AUTOSAR XML (schema 4-0-3)
standard types defined: Boolean, uint8, UInt16, UInt32, UInt8
package /AUTOSAR_Platform/DataConstrs
  range DC_Boolean: raw 0..1
  range DC_UInt16: raw 0..65535
  range DC_UInt8: raw 0..255
package /PATAC/Facility/DataTypes/Implementation
  compu method COMPU_Boolean: 0=FALSE, 1=TRUE
  unit NoUnit: factor-si-to-unit=1, offset-si-to-unit=0
package /PATAC/MSM/ComponentTypes
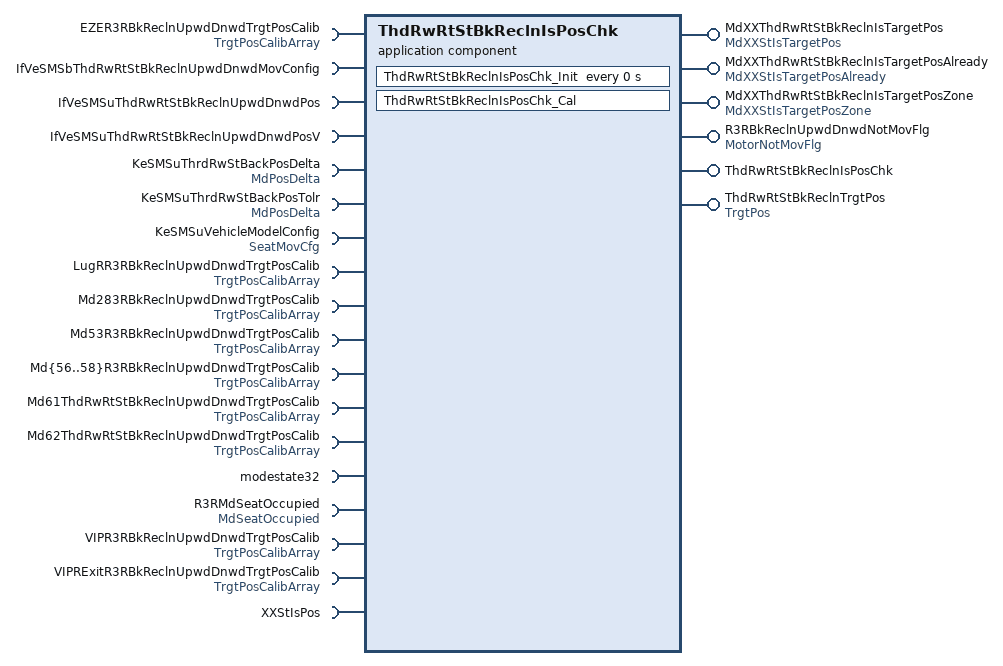
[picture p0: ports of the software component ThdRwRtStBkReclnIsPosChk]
  application sw component type ThdRwRtStBkReclnIsPosChk
    6 x provide port:
      MdXXThdRwRtStBkReclnIsTargetPos: nonqueued-sender-com-spec=data-element=MdXXStIsTargetPos/Val, provided-interface=MdXXStIsTargetPos
      MdXXThdRwRtStBkReclnIsTargetPosAlready: nonqueued-sender-com-spec=data-element=MdXXStIsTargetPosAlready/Val, provided-interface=MdXXStIsTargetPosAlready
      MdXXThdRwRtStBkReclnIsTargetPosZone: nonqueued-sender-com-spec=data-element=MdXXStIsTargetPosZone/Val, provided-interface=MdXXStIsTargetPosZone
      R3RBkReclnUpwdDnwdNotMovFlg: nonqueued-sender-com-spec{data-element=MotorNotMovFlg/Val, init-value=0}, provided-interface=MotorNotMovFlg
      ThdRwRtStBkReclnIsPosChk: server-com-spec{operation=Cal, queue-length=1}, provided-interface=ThdRwRtStBkReclnIsPosChk
      ThdRwRtStBkReclnTrgtPos: nonqueued-sender-com-spec{data-element=TrgtPos/Val, init-value=4095}, provided-interface=TrgtPos
    20 x require port:
      EZER3RBkReclnUpwdDnwdTrgtPosCalib: nonqueued-receiver-com-spec{data-element=TrgtPosArray, filter=data-filter-type=ALWAYS, init-value=[4095, 4095, 4095]}, required-interface=TrgtPosCalibArray
      IfVeSMSbThdRwRtStBkReclnUpwdDnwdMovConfig: nonqueued-receiver-com-spec{data-element=IfVeSMSbThdRwRtStBkReclnUpwdDnwdMovConfig/Val, filter=data-filter-type=ALWAYS, init-value=0}, required-interface=IfVeSMSbThdRwRtStBkReclnUpwdDnwdMovConfig
      IfVeSMSuThdRwRtStBkReclnUpwdDnwdPos: nonqueued-receiver-com-spec{data-element=IfVeSMSuThdRwRtStBkReclnUpwdDnwdPos/Val, filter=data-filter-type=ALWAYS, init-value=0}, required-interface=IfVeSMSuThdRwRtStBkReclnUpwdDnwdPos
      IfVeSMSuThdRwRtStBkReclnUpwdDnwdPosV: nonqueued-receiver-com-spec{data-element=IfVeSMSuThdRwRtStBkReclnUpwdDnwdPosV/Val, filter=data-filter-type=ALWAYS, init-value=0}, required-interface=IfVeSMSuThdRwRtStBkReclnUpwdDnwdPosV
      KeSMSuThrdRwStBackPosDelta: parameter-require-com-spec{init-value=150, parameter=MdPosDelta/Val}, required-interface=MdPosDelta
      KeSMSuThrdRwStBackPosTolr: parameter-require-com-spec{init-value=150, parameter=MdPosDelta/Val}, required-interface=MdPosDelta
      KeSMSuVehicleModelConfig: parameter-require-com-spec{init-value=2, parameter=SeatMovCfg/Val}, required-interface=SeatMovCfg
      LugRR3RBkReclnUpwdDnwdTrgtPosCalib: nonqueued-receiver-com-spec{data-element=TrgtPosArray, filter=data-filter-type=ALWAYS, init-value=[4095, 4095, 4095]}, required-interface=TrgtPosCalibArray
      Md283RBkReclnUpwdDnwdTrgtPosCalib: nonqueued-receiver-com-spec{data-element=TrgtPosArray, filter=data-filter-type=ALWAYS, init-value=[4095, 4095, 4095]}, required-interface=TrgtPosCalibArray
      Md53R3RBkReclnUpwdDnwdTrgtPosCalib: nonqueued-receiver-com-spec{data-element=TrgtPosArray, filter=data-filter-type=ALWAYS, init-value=[4095, 4095, 4095]}, required-interface=TrgtPosCalibArray
      Md{56..58}R3RBkReclnUpwdDnwdTrgtPosCalib: nonqueued-receiver-com-spec{data-element=TrgtPosArray, filter=data-filter-type=ALWAYS, init-value=[4095, 4095, 4095]}, required-interface=TrgtPosCalibArray
      Md61ThdRwRtStBkReclnUpwdDnwdTrgtPosCalib: nonqueued-receiver-com-spec{data-element=TrgtPosArray, filter=data-filter-type=ALWAYS, init-value=[4095, 4095, 4095]}, required-interface=TrgtPosCalibArray
      Md62ThdRwRtStBkReclnUpwdDnwdTrgtPosCalib: nonqueued-receiver-com-spec{data-element=TrgtPosArray, filter=data-filter-type=ALWAYS, init-value=[4095, 4095, 4095]}, required-interface=TrgtPosCalibArray
      modestate32: nonqueued-receiver-com-spec{data-element=modestate32/Val, filter=data-filter-type=ALWAYS, init-value=0}, required-interface=modestate32
      R3RMdSeatOccupied: nonqueued-receiver-com-spec{data-element=MdSeatOccupied/Val, filter=data-filter-type=ALWAYS, init-value=0}, required-interface=MdSeatOccupied
      VIPR3RBkReclnUpwdDnwdTrgtPosCalib: nonqueued-receiver-com-spec{data-element=TrgtPosArray, filter=data-filter-type=ALWAYS, init-value=[4095, 4095, 4095]}, required-interface=TrgtPosCalibArray
      VIPRExitR3RBkReclnUpwdDnwdTrgtPosCalib: nonqueued-receiver-com-spec{data-element=TrgtPosArray, filter=data-filter-type=ALWAYS, init-value=[4095, 4095, 4095]}, required-interface=TrgtPosCalibArray
      XXStIsPos: client-com-spec=Get, required-interface=XXStIsPos
    behavior ThdRwRtStBkReclnIsPosChk_InternalBehavior
      operation invoked event OIT_ThdRwRtStBkReclnIsPosChk_Cal_ThdRwRtStBkReclnIsPosChk_Cal: start-on-event=ThdRwRtStBkReclnIsPosChk_Cal, operation=ThdRwRtStBkReclnIsPosChk.Cal
      timing event ThdRwRtStBkReclnIsPosChk_InitEvent: start-on-event=ThdRwRtStBkReclnIsPosChk_Init, period=0
      runnable ThdRwRtStBkReclnIsPosChk_Cal
        data-receive-point-by-arguments:
          16 x access:
            REC_EZER3RBkReclnUpwdDnwdTrgtPosCalib_TrgtPosArray: accessed-variable=EZER3RBkReclnUpwdDnwdTrgtPosCalib.TrgtPosArray
            REC_IfVeSMSbThdRwRtStBkReclnUpwdDnwdMovConfig_Val: accessed-variable=IfVeSMSbThdRwRtStBkReclnUpwdDnwdMovConfig.Val
            REC_IfVeSMSuThdRwRtStBkReclnUpwdDnwdPos_Val: accessed-variable=IfVeSMSuThdRwRtStBkReclnUpwdDnwdPos.Val
            REC_IfVeSMSuThdRwRtStBkReclnUpwdDnwdPosV_Val: accessed-variable=IfVeSMSuThdRwRtStBkReclnUpwdDnwdPosV.Val
            REC_LugRR3RBkReclnUpwdDnwdTrgtPosCalib_TrgtPosArray: accessed-variable=LugRR3RBkReclnUpwdDnwdTrgtPosCalib.TrgtPosArray
            REC_Md283RBkReclnUpwdDnwdTrgtPosCalib_TrgtPosArray: accessed-variable=Md283RBkReclnUpwdDnwdTrgtPosCalib.TrgtPosArray
            REC_Md53R3RBkReclnUpwdDnwdTrgtPosCalib_TrgtPosArray: accessed-variable=Md53R3RBkReclnUpwdDnwdTrgtPosCalib.TrgtPosArray
            REC_Md{56..58}R3RBkReclnUpwdDnwdTrgtPosCalib_TrgtPosArray: accessed-variable=Md{56..58}R3RBkReclnUpwdDnwdTrgtPosCalib.TrgtPosArray
            REC_Md61ThdRwRtStBkReclnUpwdDnwdTrgtPosCalib_TrgtPosArray: accessed-variable=Md61ThdRwRtStBkReclnUpwdDnwdTrgtPosCalib.TrgtPosArray
            REC_Md62ThdRwRtStBkReclnUpwdDnwdTrgtPosCalib_TrgtPosArray: accessed-variable=Md62ThdRwRtStBkReclnUpwdDnwdTrgtPosCalib.TrgtPosArray
            REC_modestate32_Val: accessed-variable=modestate32.Val
            REC_R3RMdSeatOccupied_Val: accessed-variable=R3RMdSeatOccupied.Val
            REC_VIPR3RBkReclnUpwdDnwdTrgtPosCalib_TrgtPosArray: accessed-variable=VIPR3RBkReclnUpwdDnwdTrgtPosCalib.TrgtPosArray
            REC_VIPRExitR3RBkReclnUpwdDnwdTrgtPosCalib_TrgtPosArray: accessed-variable=VIPRExitR3RBkReclnUpwdDnwdTrgtPosCalib.TrgtPosArray
        data-send-points:
          5 x access:
            SEND_MdXXThdRwRtStBkReclnIsTargetPos_Val: accessed-variable=MdXXThdRwRtStBkReclnIsTargetPos.Val
            SEND_MdXXThdRwRtStBkReclnIsTargetPosAlready_Val: accessed-variable=MdXXThdRwRtStBkReclnIsTargetPosAlready.Val
            SEND_MdXXThdRwRtStBkReclnIsTargetPosZone_Val: accessed-variable=MdXXThdRwRtStBkReclnIsTargetPosZone.Val
            SEND_R3RBkReclnUpwdDnwdNotMovFlg_Val: accessed-variable=R3RBkReclnUpwdDnwdNotMovFlg.Val
            SEND_ThdRwRtStBkReclnTrgtPos_Val: accessed-variable=ThdRwRtStBkReclnTrgtPos.Val
        parameter access PA_KeSMSuThrdRwStBackPosDelta_Val: accessed-parameter=KeSMSuThrdRwStBackPosDelta.Val
        parameter access PA_KeSMSuThrdRwStBackPosTolr_Val: accessed-parameter=KeSMSuThrdRwStBackPosTolr.Val
        parameter access PA_KeSMSuVehicleModelConfig_Val: accessed-parameter=KeSMSuVehicleModelConfig.Val
        sync call SC_XXStIsPos_Get: operation=XXStIsPos.Get, timeout=0
      runnable ThdRwRtStBkReclnIsPosChk_Init
        parameter access PA_KeSMSuThrdRwStBackPosDelta_Val: accessed-parameter=KeSMSuThrdRwStBackPosDelta.Val
        parameter access PA_KeSMSuThrdRwStBackPosTolr_Val: accessed-parameter=KeSMSuThrdRwStBackPosTolr.Val
        parameter access PA_KeSMSuVehicleModelConfig_Val: accessed-parameter=KeSMSuVehicleModelConfig.Val
  swc implementation ThdRwRtStBkReclnIsPosChk_Implementation: behavior=ThdRwRtStBkReclnIsPosChk_InternalBehavior
    code-descriptors:
      code Default: artifact-descriptors=autosar-engineering-object={short-label=Default, category=SWSRC}
package /PATAC/MSM/DataTypes
  parameter interface SeatMovCfg
    parameter data prototype Val: sw-calibration-access=READ-WRITE, type=UInt8
package /PATAC/MSM/ModeAdjust/CalPortInterface
  parameter interface MdPosDelta
    parameter data prototype Val: sw-calibration-access=READ-WRITE, type=UInt16
package /PATAC/MSM/ModeAdjust/DataType
  impl type TrgtPosCalibArray: category=ARRAY, sw-calibration-access=READ-ONLY, type-emitter=RTE  # 0:pos 1:max 2:min
    element Element: array-size=3, array-size-semantics=FIXED-SIZE, implementation-data-type=UInt16, invalid-value=0
package /PATAC/MSM/ModeAdjust/Interfaces
  sender receiver interface IfVeSMSuThdRwRtStBkReclnUpwdDnwdPosV: invalidation-policy{data-element=IfVeSMSuThdRwRtStBkReclnUpwdDnwdPosV/Val, handle-invalid=DONT-INVALIDATE}
    data Val: type=Implementation/Boolean
package /PATAC/MSM/ModeAdjust/PortInterface
  client server interface ThdRwRtStBkReclnIsPosChk
    operation Cal
  client server interface XXStIsPos
    operation Get
      8 x arg, all with server-argument-impl-policy=USE-ARGUMENT-TYPE:
        PosV: type=DataTypes/Boolean, direction=IN
        Pos: type=UInt16, direction=IN
        CalibArray: type=TrgtPosCalibArray, direction=IN
        Delta: type=UInt16, direction=IN
        Tolr: type=UInt16, direction=IN
        IsPos: type=DataTypes/Boolean, direction=OUT
        IsPosZone: type=DataTypes/Boolean, direction=OUT
        IsPosAlready: type=DataTypes/Boolean, direction=OUT
  7 x sender receiver interface:
    MdSeatOccupied: invalidation-policy{data-element=MdSeatOccupied/Val, handle-invalid=DONT-INVALIDATE}
      data Val: type=Implementation/Boolean
    MdXXStIsTargetPos: invalidation-policy{data-element=MdXXStIsTargetPos/Val, handle-invalid=DONT-INVALIDATE}
      data Val: type=UInt32
    MdXXStIsTargetPosAlready: invalidation-policy{data-element=MdXXStIsTargetPosAlready/Val, handle-invalid=DONT-INVALIDATE}
      data Val: type=UInt32
    MdXXStIsTargetPosZone: invalidation-policy{data-element=MdXXStIsTargetPosZone/Val, handle-invalid=DONT-INVALIDATE}
      data Val: type=UInt32
    modestate32: invalidation-policy{data-element=modestate32/Val, handle-invalid=DONT-INVALIDATE}
      data Val: type=UInt32
    MotorNotMovFlg: invalidation-policy{data-element=MotorNotMovFlg/Val, handle-invalid=DONT-INVALIDATE}
      data Val: type=Implementation/Boolean
    TrgtPosCalibArray: invalidation-policy{data-element=TrgtPosArray, handle-invalid=DONT-INVALIDATE}
      data TrgtPosArray: type=TrgtPosCalibArray  # 0:Pos 1:Max 2:Min
package /PATAC/MSM/PortInterfaces
  sender receiver interface IfVeSMSbThdRwRtStBkReclnUpwdDnwdMovConfig: invalidation-policy{data-element=IfVeSMSbThdRwRtStBkReclnUpwdDnwdMovConfig/Val, handle-invalid=DONT-INVALIDATE}
    data Val: type=Implementation/Boolean
  sender receiver interface IfVeSMSuThdRwRtStBkReclnUpwdDnwdPos: invalidation-policy{data-element=IfVeSMSuThdRwRtStBkReclnUpwdDnwdPos/Val, handle-invalid=DONT-INVALIDATE}
    data Val: type=UInt16
  sender receiver interface TrgtPos: invalidation-policy{data-element=TrgtPos/Val, handle-invalid=DONT-INVALIDATE}
    data Val: type=UInt16
